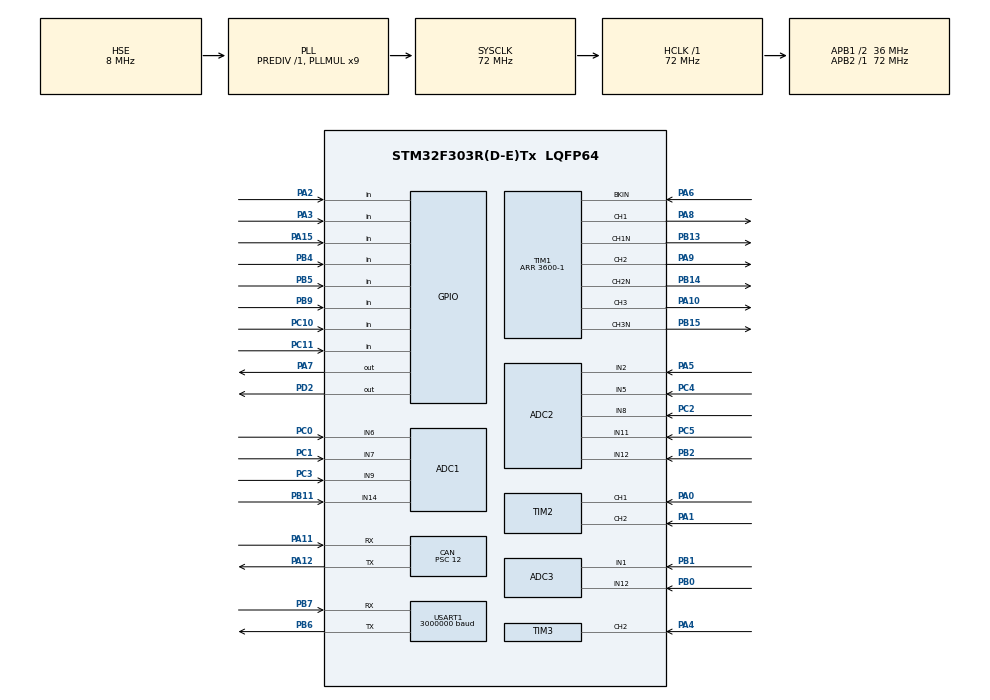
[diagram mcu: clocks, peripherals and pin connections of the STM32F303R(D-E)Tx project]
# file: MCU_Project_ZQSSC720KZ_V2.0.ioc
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ADC1.Channel-0\#ChannelRegularConversion=ADC_CHANNEL_6
ADC1.Channel-1\#ChannelRegularConversion=ADC_CHANNEL_7
ADC1.Channel-2\#ChannelRegularConversion=ADC_CHANNEL_9
ADC1.Channel-3\#ChannelRegularConversion=ADC_CHANNEL_14
ADC1.DMAContinuousRequests=ENABLE
ADC1.ExternalTrigConv=ADC_EXTERNALTRIGCONV_T4_TRGO
ADC1.NbrOfConversion=4
ADC1.NbrOfConversionFlag=1
ADC1.Offset-0\#ChannelRegularConversion=0
ADC1.Offset-1\#ChannelRegularConversion=0
ADC1.Offset-2\#ChannelRegularConversion=0
ADC1.Offset-3\#ChannelRegularConversion=0
ADC1.OffsetNumber-0\#ChannelRegularConversion=ADC_OFFSET_NONE
ADC1.OffsetNumber-1\#ChannelRegularConversion=ADC_OFFSET_NONE
ADC1.OffsetNumber-2\#ChannelRegularConversion=ADC_OFFSET_NONE
ADC1.OffsetNumber-3\#ChannelRegularConversion=ADC_OFFSET_NONE
ADC1.Rank-0\#ChannelRegularConversion=1
ADC1.Rank-1\#ChannelRegularConversion=2
ADC1.Rank-2\#ChannelRegularConversion=3
ADC1.Rank-3\#ChannelRegularConversion=4
ADC1.SamplingTime-0\#ChannelRegularConversion=ADC_SAMPLETIME_181CYCLES_5
ADC1.SamplingTime-1\#ChannelRegularConversion=ADC_SAMPLETIME_181CYCLES_5
ADC1.SamplingTime-2\#ChannelRegularConversion=ADC_SAMPLETIME_181CYCLES_5
ADC1.SamplingTime-3\#ChannelRegularConversion=ADC_SAMPLETIME_181CYCLES_5
ADC1.SamplingTimeOPAMP-2\#ChannelRegularConversion=ADC_SAMPLETIME_61CYCLES_5
ADC1.SamplingTimeOPAMP-3\#ChannelRegularConversion=ADC_SAMPLETIME_61CYCLES_5
ADC1.master=1
ADC2.EnableRegularConversion=DISABLE
ADC2.ExternalTrigInjecConv=ADC_EXTERNALTRIGINJECCONV_T1_CC4
ADC2.InjNumberOfConversion=3
ADC2.InjectedChannel-10\#ChannelInjectedConversion=ADC_CHANNEL_5
ADC2.InjectedChannel-8\#ChannelInjectedConversion=ADC_CHANNEL_12
ADC2.InjectedChannel-9\#ChannelInjectedConversion=ADC_CHANNEL_8
ADC2.InjectedOffset-10\#ChannelInjectedConversion=0
ADC2.InjectedOffset-8\#ChannelInjectedConversion=0
ADC2.InjectedOffset-9\#ChannelInjectedConversion=0
ADC2.InjectedOffsetNumber-10\#ChannelInjectedConversion=ADC_OFFSET_NONE
ADC2.InjectedOffsetNumber-8\#ChannelInjectedConversion=ADC_OFFSET_NONE
ADC2.InjectedOffsetNumber-9\#ChannelInjectedConversion=ADC_OFFSET_NONE
ADC2.InjectedRank-10\#ChannelInjectedConversion=3
ADC2.InjectedRank-8\#ChannelInjectedConversion=1
ADC2.InjectedRank-9\#ChannelInjectedConversion=2
ADC2.InjectedSamplingTime-10\#ChannelInjectedConversion=ADC_SAMPLETIME_7CYCLES_5
ADC2.InjectedSamplingTime-8\#ChannelInjectedConversion=ADC_SAMPLETIME_7CYCLES_5
ADC2.InjectedSamplingTime-9\#ChannelInjectedConversion=ADC_SAMPLETIME_7CYCLES_5
ADC2.InjectedSamplingTimeOPAMP-10\#ChannelInjectedConversion=ADC_SAMPLETIME_61CYCLES_5
ADC2.InjectedSamplingTimeOPAMP-8\#ChannelInjectedConversion=ADC_SAMPLETIME_61CYCLES_5
ADC2.InjectedSamplingTimeOPAMP-9\#ChannelInjectedConversion=ADC_SAMPLETIME_61CYCLES_5
ADC2.Rank1_Channel=ADC_CHANNEL_12
ADC2.Rank2_Channel=ADC_CHANNEL_8
ADC2.Rank3_Channel=ADC_CHANNEL_5
ADC3.EnableRegularConversion=DISABLE
ADC3.ExternalTrigInjecConv=ADC_EXTERNALTRIGINJECCONV_T1_CC4
ADC3.InjNumberOfConversion=2
ADC3.InjectedChannel-2\#ChannelInjectedConversion=ADC_CHANNEL_1
ADC3.InjectedChannel-3\#ChannelInjectedConversion=ADC_CHANNEL_12
ADC3.InjectedOffset-2\#ChannelInjectedConversion=0
ADC3.InjectedOffset-3\#ChannelInjectedConversion=0
ADC3.InjectedOffsetNumber-2\#ChannelInjectedConversion=ADC_OFFSET_NONE
ADC3.InjectedOffsetNumber-3\#ChannelInjectedConversion=ADC_OFFSET_NONE
ADC3.InjectedRank-2\#ChannelInjectedConversion=1
ADC3.InjectedRank-3\#ChannelInjectedConversion=2
ADC3.InjectedSamplingTime-2\#ChannelInjectedConversion=ADC_SAMPLETIME_7CYCLES_5
ADC3.InjectedSamplingTime-3\#ChannelInjectedConversion=ADC_SAMPLETIME_7CYCLES_5
ADC3.InjectedSamplingTimeOPAMP-2\#ChannelInjectedConversion=ADC_SAMPLETIME_61CYCLES_5
ADC3.InjectedSamplingTimeOPAMP-3\#ChannelInjectedConversion=ADC_SAMPLETIME_61CYCLES_5
ADC3.master=1
CAN.ABOM=ENABLE
CAN.BS1=CAN_BS1_3TQ
CAN.BS2=CAN_BS2_2TQ
CAN.CalculateBaudRate=499999
CAN.CalculateTimeBit=2000
CAN.CalculateTimeQuantum=333.33333333333337
CAN.NART=ENABLE
CAN.Prescaler=12
Dma.ADC1.0.Direction=DMA_PERIPH_TO_MEMORY
Dma.ADC1.0.Instance=DMA1_Channel1
Dma.ADC1.0.MemDataAlignment=DMA_MDATAALIGN_HALFWORD
Dma.ADC1.0.MemInc=DMA_MINC_ENABLE
Dma.ADC1.0.Mode=DMA_CIRCULAR
Dma.ADC1.0.PeriphDataAlignment=DMA_PDATAALIGN_HALFWORD
Dma.ADC1.0.PeriphInc=DMA_PINC_DISABLE
Dma.ADC1.0.Priority=DMA_PRIORITY_LOW
Dma.Request0=ADC1
Mcu.Family=STM32F3
Mcu.Name=STM32F303R(D-E)Tx
Mcu.Package=LQFP64
NVIC.CAN_RX1_IRQn=true\:1\:0\:true\:false\:true\:true\:true\:true
NVIC.CAN_SCE_IRQn=true\:1\:0\:true\:false\:true\:true\:true\:true
NVIC.DMA1_Channel1_IRQn=true\:0\:0\:false\:false\:true\:false\:true\:true
NVIC.FPU_IRQn=true\:3\:0\:true\:false\:true\:true\:false\:true
NVIC.PriorityGroup=NVIC_PRIORITYGROUP_4
NVIC.TIM1_UP_TIM16_IRQn=true\:0\:0\:false\:false\:true\:true\:true\:true
NVIC.TIM3_IRQn=true\:1\:0\:true\:false\:true\:true\:true\:true
NVIC.TIM6_DAC_IRQn=true\:2\:0\:true\:false\:true\:true\:true\:true
NVIC.USB_LP_CAN_RX0_IRQn=true\:1\:0\:true\:false\:true\:true\:true\:true
PA0.Signal=S_TIM2_CH1_ETR
PA1.Signal=S_TIM2_CH2
PA10.Signal=S_TIM1_CH3
PA11.Mode=CAN_Activate
PA11.Signal=CAN_RX
PA12.Mode=CAN_Activate
PA12.Signal=CAN_TX
PA13.Mode=Serial_Wire
PA13.Signal=SYS_JTMS-SWDIO
PA14.Mode=Serial_Wire
PA14.Signal=SYS_JTCK-SWCLK
PA15.Signal=GPIO_Input
PA2.Signal=GPIO_Input
PA3.Signal=GPIO_Input
PA4.Signal=S_TIM3_CH2
PA5.Mode=IN2-Single-Ended
PA5.Signal=ADC2_IN2
PA6.Mode=Activate-Break-Input
PA6.Signal=TIM1_BKIN
PA7.Signal=GPIO_Output
PA8.Signal=S_TIM1_CH1
PA9.Signal=S_TIM1_CH2
PB0.Mode=IN12-Single-Ended
PB0.Signal=ADC3_IN12
PB1.Mode=IN1-Single-Ended
PB1.Signal=ADC3_IN1
PB11.Mode=IN14-Single-Ended
PB11.Signal=ADC1_IN14
PB13.Mode=PWM Generation1 CH1 CH1N
PB13.Signal=TIM1_CH1N
PB14.Mode=PWM Generation2 CH2 CH2N
PB14.Signal=TIM1_CH2N
PB15.Mode=PWM Generation3 CH3 CH3N
PB15.Signal=TIM1_CH3N
PB2.Mode=IN12-Single-Ended
PB2.Signal=ADC2_IN12
PB4.Signal=GPIO_Input
PB5.Signal=GPIO_Input
PB6.Mode=Asynchronous
PB6.Signal=USART1_TX
PB7.Mode=Asynchronous
PB7.Signal=USART1_RX
PB9.Signal=GPIO_Input
PC0.Signal=ADCx_IN6
PC1.Signal=ADCx_IN7
PC10.Signal=GPIO_Input
PC11.Signal=GPIO_Input
PC2.Signal=ADCx_IN8
PC3.Signal=ADCx_IN9
PC4.Mode=IN5-Single-Ended
PC4.Signal=ADC2_IN5
PC5.Mode=IN11-Single-Ended
PC5.Signal=ADC2_IN11
PD2.Signal=GPIO_Output
PF0-OSC_IN.Mode=HSE-External-Oscillator
PF0-OSC_IN.Signal=RCC_OSC_IN
PF1-OSC_OUT.Mode=HSE-External-Oscillator
PF1-OSC_OUT.Signal=RCC_OSC_OUT
ProjectManager.HeapSize=0x200
ProjectManager.StackSize=0x400
ProjectManager.TargetToolchain=CMake
RCC.AHBFreq_Value=72000000
RCC.APB1CLKDivider=RCC_HCLK_DIV2
RCC.APB1Freq_Value=36000000
RCC.APB1TimFreq_Value=72000000
RCC.APB2Freq_Value=72000000
RCC.APB2TimFreq_Value=72000000
RCC.CortexFreq_Value=72000000
RCC.HCLKFreq_Value=72000000
RCC.HSE_VALUE=8000000
RCC.HSI_VALUE=8000000
RCC.LSE_VALUE=32768
RCC.PLLMUL=RCC_PLL_MUL9
RCC.PLLSourceVirtual=RCC_PLLSOURCE_HSE
RCC.SYSCLKFreq_VALUE=72000000
RCC.SYSCLKSourceVirtual=RCC_SYSCLKSOURCE_PLLCLK
RCC.USBFreq_Value=72000000
SH.ADCx_IN6.0=ADC1_IN6,IN6-Single-Ended
SH.ADCx_IN7.0=ADC1_IN7,IN7-Single-Ended
SH.ADCx_IN8.0=ADC2_IN8,IN8-Single-Ended
SH.ADCx_IN9.0=ADC1_IN9,IN9-Single-Ended
SH.S_TIM1_CH1.0=TIM1_CH1,PWM Generation1 CH1 CH1N
SH.S_TIM1_CH2.0=TIM1_CH2,PWM Generation2 CH2 CH2N
SH.S_TIM1_CH3.0=TIM1_CH3,PWM Generation3 CH3 CH3N
SH.S_TIM2_CH1_ETR.0=TIM2_CH1,Encoder_Interface
SH.S_TIM2_CH2.0=TIM2_CH2,Encoder_Interface
SH.S_TIM3_CH2.0=TIM3_CH2,Input_Capture2_from_TI2
TIM1.AutoReloadPreload=TIM_AUTORELOAD_PRELOAD_DISABLE
TIM1.AutomaticOutput=TIM_AUTOMATICOUTPUT_ENABLE
TIM1.BreakFilter=0
TIM1.BreakPolarity=TIM_BREAKPOLARITY_LOW
TIM1.Channel-PWM\ Generation1\ CH1\ CH1N=TIM_CHANNEL_1
TIM1.Channel-PWM\ Generation2\ CH2\ CH2N=TIM_CHANNEL_2
TIM1.Channel-PWM\ Generation3\ CH3\ CH3N=TIM_CHANNEL_3
TIM1.Channel-PWM\ Generation4\ No\ Output=TIM_CHANNEL_4
TIM1.CounterMode=TIM_COUNTERMODE_CENTERALIGNED1
TIM1.DeadTime=100
TIM1.OCMode_PWM-PWM\ Generation4\ No\ Output=TIM_OCMODE_PWM2
TIM1.Period=3600-1
TIM1.Pulse-PWM\ Generation1\ CH1\ CH1N=900
TIM1.Pulse-PWM\ Generation2\ CH2\ CH2N=900
TIM1.Pulse-PWM\ Generation3\ CH3\ CH3N=900
TIM1.RepetitionCounter=1
TIM1.TIM_MasterOutputTrigger=TIM_TRGO_OC4REF
TIM1.TIM_MasterOutputTrigger2=TIM_TRGO2_UPDATE
TIM2.EncoderMode=TIM_ENCODERMODE_TI12
TIM2.IC1Filter=10
TIM2.IC2Filter=10
TIM3.Channel-Input_Capture2_from_TI2=TIM_CHANNEL_2
TIM3.ICFilter_CH2=10
TIM4.Period=7200-1
TIM4.Prescaler=10-1
TIM4.TIM_MasterOutputTrigger=TIM_TRGO_UPDATE
TIM6.Period=1000-1
TIM6.Prescaler=72-1
USART1.BaudRate=3000000
USART1.VirtualMode-Asynchronous=VM_ASYNC
VP_TIM1_VS_ClockSourceINT.Mode=Internal
VP_TIM1_VS_NoETR.Mode=ETR_as_clearing_source_through_ADC_remap_TIM1
VP_TIM1_VS_no_output4.Mode=PWM Generation4 No Output
VP_TIM4_VS_ClockSourceITR.Mode=TriggerSource_ITR0
VP_TIM6_VS_ClockSourceINT.Mode=Enable_Timer
board=custom

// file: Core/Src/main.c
/* USER CODE BEGIN Header */
/**
  ******************************************************************************
  * @file           : main.c
  * @brief          : Main program body
  ******************************************************************************
  * @attention
  *
  * Copyright (c) 2026 STMicroelectronics.
  * All rights reserved.
  *
  * This software is licensed under terms that can be found in the LICENSE file
  * in the root directory of this software component.
  * If no LICENSE file comes with this software, it is provided AS-IS.
  *
  ******************************************************************************
  */
/* USER CODE END Header */
#include "main.h"
#include "adc.h"
#include "can.h"
#include "dma.h"
#include "tim.h"
#include "usart.h"
#include "gpio.h"

/* USER CODE BEGIN Includes */
#include "System.h"
/* USER CODE END Includes */

void SystemClock_Config(void);

int main(void)
{

  /* MCU Configuration--------------------------------------------------------*/

  /* Reset of all peripherals, Initializes the Flash interface and the Systick. */
  HAL_Init();

  /* Configure the system clock */
  SystemClock_Config();

  /* Initialize all configured peripherals */
  MX_GPIO_Init();
  MX_DMA_Init();
  MX_TIM1_Init();
  MX_ADC1_Init();
  MX_ADC2_Init();
  MX_ADC3_Init();
  MX_TIM2_Init();
  MX_TIM3_Init();
  MX_TIM4_Init();
  MX_USART1_UART_Init();
  MX_TIM6_Init();
  MX_CAN_Init();
  /* USER CODE BEGIN 2 */
  if (!System_Init())
  {
    Error_Handler();
  }
  /* USER CODE END 2 */

  /* Infinite loop */
  while (1)
  {

    /* USER CODE BEGIN 3 */
    System_MainFunction();
  }
  /* USER CODE END 3 */
}

void SystemClock_Config(void)
{
  RCC_OscInitTypeDef RCC_OscInitStruct = {0};
  RCC_ClkInitTypeDef RCC_ClkInitStruct = {0};
  RCC_PeriphCLKInitTypeDef PeriphClkInit = {0};

  /** Initializes the RCC Oscillators according to the specified parameters
  * in the RCC_OscInitTypeDef structure.
  */
  RCC_OscInitStruct.OscillatorType = RCC_OSCILLATORTYPE_HSE;
  RCC_OscInitStruct.HSEState = RCC_HSE_ON;
  RCC_OscInitStruct.HSIState = RCC_HSI_ON;
  RCC_OscInitStruct.PLL.PLLState = RCC_PLL_ON;
  RCC_OscInitStruct.PLL.PLLSource = RCC_PLLSOURCE_HSE;
  RCC_OscInitStruct.PLL.PLLMUL = RCC_PLL_MUL9;
  RCC_OscInitStruct.PLL.PREDIV = RCC_PREDIV_DIV1;
  if (HAL_RCC_OscConfig(&RCC_OscInitStruct) != HAL_OK)
  {
    Error_Handler();
  }

  /** Initializes the CPU, AHB and APB buses clocks
  */
  RCC_ClkInitStruct.ClockType = RCC_CLOCKTYPE_HCLK|RCC_CLOCKTYPE_SYSCLK
                              |RCC_CLOCKTYPE_PCLK1|RCC_CLOCKTYPE_PCLK2;
  RCC_ClkInitStruct.SYSCLKSource = RCC_SYSCLKSOURCE_PLLCLK;
  RCC_ClkInitStruct.AHBCLKDivider = RCC_SYSCLK_DIV1;
  RCC_ClkInitStruct.APB1CLKDivider = RCC_HCLK_DIV2;
  RCC_ClkInitStruct.APB2CLKDivider = RCC_HCLK_DIV1;

  if (HAL_RCC_ClockConfig(&RCC_ClkInitStruct, FLASH_LATENCY_2) != HAL_OK)
  {
    Error_Handler();
  }
  PeriphClkInit.PeriphClockSelection = RCC_PERIPHCLK_USART1|RCC_PERIPHCLK_TIM1
                              |RCC_PERIPHCLK_ADC12|RCC_PERIPHCLK_ADC34
                              |RCC_PERIPHCLK_TIM2|RCC_PERIPHCLK_TIM34;
  PeriphClkInit.Usart1ClockSelection = RCC_USART1CLKSOURCE_PCLK2;
  PeriphClkInit.Adc12ClockSelection = RCC_ADC12PLLCLK_DIV1;
  PeriphClkInit.Adc34ClockSelection = RCC_ADC34PLLCLK_DIV1;
  PeriphClkInit.Tim1ClockSelection = RCC_TIM1CLK_HCLK;
  PeriphClkInit.Tim2ClockSelection = RCC_TIM2CLK_HCLK;
  PeriphClkInit.Tim34ClockSelection = RCC_TIM34CLK_HCLK;
  if (HAL_RCCEx_PeriphCLKConfig(&PeriphClkInit) != HAL_OK)
  {
    Error_Handler();
  }
}

void Error_Handler(void)
{
  __disable_irq();
  while (1)
  {
  }
}
